# LPC43xx register map
File version: 10
CPU: CM4 r0p0, little endian, no MPU, no FPU, 3 interrupt priority bits
Registers are 32-bit, read-write, reset 0x0 unless marked. A register's access mark holds for its fields unless they carry their own. Offsets are from the block's base; [hi:lo] are bit positions; {n}, {i} and the like mark numbered series; 'fields as' and 'values as' point back to an identical list.

## SCU — System Control Unit (SCU) I/O configuration
Base 0x40086000
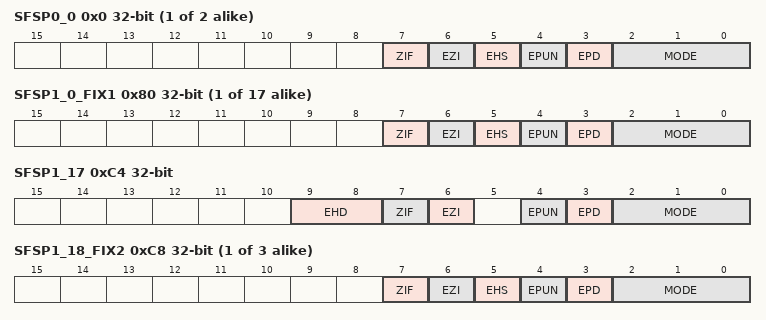
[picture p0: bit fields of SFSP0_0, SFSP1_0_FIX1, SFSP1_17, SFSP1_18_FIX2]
{0x0+4i} SFSP0_{i} (i=0..1) — Pin configuration register for pins P0
  [7] ZIF — Input glitch filter. Disable the input glitch filter for clocking signals higher than 30 MHz.
    0=ENABLE_INPUT_GLITCH (Enable input glitch filter); 1=DISABLE_INPUT_GLITCH (Disable input glitch filter)
  [6] EZI — Input buffer enable. The input buffer is disabled by default at reset and must be enabled for receiving.
    0=DISABLE_INPUT_BUFFER; 1=ENABLE_INPUT_BUFFER
  [5] EHS — Select Slew rate.
    0=SLOW_LOW_NOISE_WITH (Slow (low noise with medium speed)); 1=FAST_MEDIUM_NOISE_W (Fast (medium noise with fast speed))
  [4] EPUN — Disable pull-up resistor at pad. By default, the pull-up resistor is enabled at reset.
    0=ENABLE_PULL_UP (Enable pull-up. Enable both pull-down resistor and pull-up resistor for repeater mode.); 1=DISABLE_PULL_UP
  [3] EPD — Enable pull-down resistor at pad.
    0=DISABLE_PULL_DOWN; 1=ENABLE_PULL_DOWN (Enable pull-down.Enable both pull-down resistor and pull-up resistor for repeater mode.)
  [2:0] MODE — Select pin function.
    0=FUNCTION_0_DEFAULT; {v}=FUNCTION_{v} (v=1..7)
{0x80+4i} SFSP1_{i}_FIX1 (i=0..16) — Pin configuration register for pins P1
  fields as SFSP0_0
0xC4 SFSP1_17 — Pin configuration register for pins P1_17
  [9:8] EHD — Select drive strength.
    0=NORMAL_DRIVE_4_MA_D (Normal-drive: 4 mA drive strength); 1=MEDIUM_DRIVE_8_MA_D (Medium-drive: 8 mA drive strength); 2=HIGH_DRIVE_14_MA_DR (High-drive: 14 mA drive strength); 3=ULTRA_HIGH_DRIVE_20 (Ultra high-drive: 20 mA drive strength)
  [7] ZIF — Input glitch filter. Disable the input glitch filter for clocking signals higher than 30 MHz.
    values as SFSP0_0.ZIF
  [6] EZI — Input buffer enable. The input buffer is disabled by default at reset but must be enabled to transfer data from the I/O buffer to the pad.
    0=DISABLE_INPUT_BUFFER; 1=ENABLE_INPUT_BUFFER
  [4] EPUN — Disable pull-up resistor at pad. By default, the pull-up resistor is enabled at reset.
    values as SFSP0_0.EPUN
  [3] EPD — Enable pull-down resistor at pad.
    0=DISABLE_PULL_DOWN; 1=ENABLE_PULL_DOWN (Enable pull-down. Enable both pull-down resistor and pull-up resistor for repeater mode.)
  [2:0] MODE — Select pin function.
    0=FUNCTION_0_DEFAULT; {v}=FUNCTION_{v} (v=1..7)
{0x80+4i} SFSP1_{i}_FIX2 (i=18..20) — Pin configuration register for pins P1
  fields as SFSP0_0
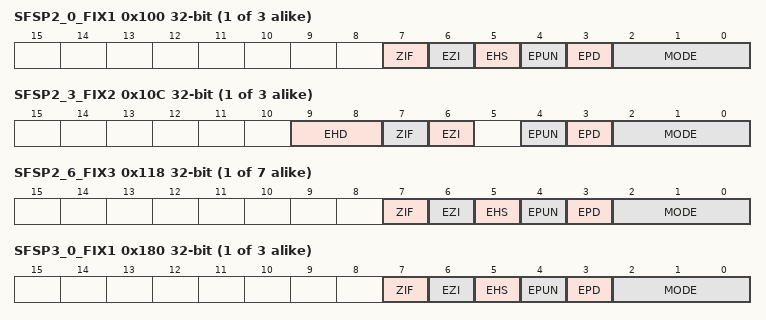
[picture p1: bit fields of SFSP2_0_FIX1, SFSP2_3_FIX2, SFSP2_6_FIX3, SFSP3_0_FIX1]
{0x100+4i} SFSP2_{i}_FIX1 (i=0..2) — Pin configuration register for pins P2
  fields as SFSP0_0
{0x100+4i} SFSP2_{i}_FIX2 (i=3..5) — Pin configuration register for pins P2
  fields as SFSP1_17
{0x100+4i} SFSP2_{i}_FIX3 (i=6..12) — Pin configuration register for pins P2
  fields as SFSP0_0
{0x180+4i} SFSP3_{i}_FIX1 (i=0..2) — Pin configuration register for pins P3
  fields as SFSP0_0
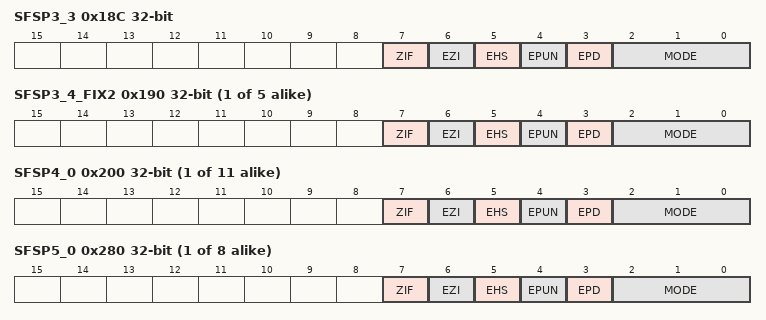
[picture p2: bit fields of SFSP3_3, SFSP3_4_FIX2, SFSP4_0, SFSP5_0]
0x18C SFSP3_3 — Pin configuration register for pins P3
  [7] ZIF — Input glitch filter. Disable the input glitch filter for clocking signals higher than 30 MHz.
    0=ENABLE_INPUT_FILTER; 1=DISABLE_INPUT_FILTER
  [6] EZI — Input buffer enable. The input buffer is disabled by default at reset and must be enabled for receiving.
    0=DISABLE_INPUT_BUFFER; 1=ENABLE_INPUT_BUFFER
  [5] EHS — Slew rate
    0=FAST_LOW_NOISE_WITH (Fast (low noise with fast speed)); 1=HIGH_SPEED_MEDIUM_N (High-speed (medium noise with high speed))
  [4] EPUN — Disable pull-up resistor at pad. By default, the pull-up resistor is enabled at reset.
    values as SFSP0_0.EPUN
  [3] EPD — Enable pull-down resistor at pad.
    values as SFSP1_17.EPD
  [2:0] MODE — Select pin function.
    0=FUNCTION_0_DEFAULT; {v}=FUNCTION_{v} (v=1..7)
{0x180+4i} SFSP3_{i}_FIX2 (i=4..8) — Pin configuration register for pins P3
  fields as SFSP0_0
{0x200+4i} SFSP4_{i} (i=0..10) — Pin configuration register for pins P4
  fields as SFSP0_0
{0x280+4i} SFSP5_{i} (i=0..7) — Pin configuration register for pins P5
  fields as SFSP0_0
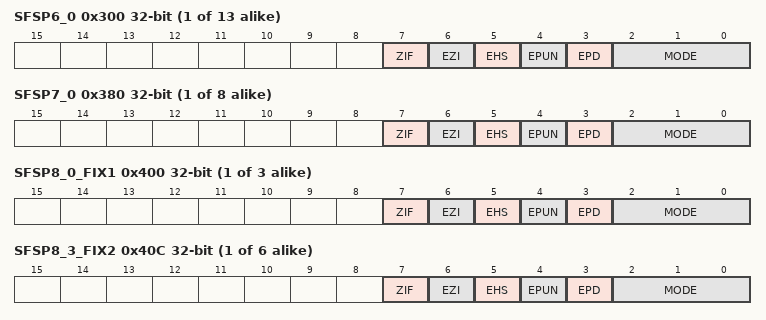
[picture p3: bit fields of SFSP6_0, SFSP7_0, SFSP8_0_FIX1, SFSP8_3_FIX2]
{0x300+4i} SFSP6_{i} (i=0..12) — Pin configuration register for pins P6
  fields as SFSP0_0
{0x380+4i} SFSP7_{i} (i=0..7) — Pin configuration register for pins P7
  fields as SFSP0_0
{0x400+4i} SFSP8_{i}_FIX1 (i=0..2) — Pin configuration register for pins P8
  fields as SFSP0_0
{0x400+4i} SFSP8_{i}_FIX2 (i=3..8) — Pin configuration register for pins P8
  fields as SFSP0_0
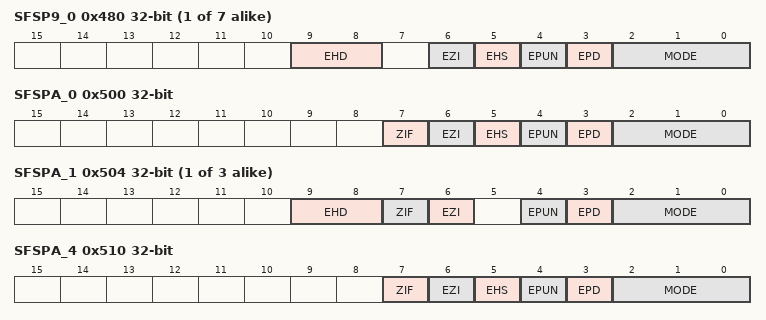
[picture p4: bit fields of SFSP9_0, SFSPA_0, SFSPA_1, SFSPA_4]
{0x480+4i} SFSP9_{i} (i=0..6) — Pin configuration register for pins P9
  [9:8] EHD — Select drive strength
    0=STANDARD_DRIVE_4_MA (Standard drive: 4 mA drive strength); 1=MEDIUM_DRIVE_8_MA_D (Medium drive: 8 mA drive strength); 2=HIGH_DRIVE_14_MA_DR (High drive: 14 mA drive strength); 3=ULTRA_HIGH_DRIVE_20 (Ultra-high drive: 20 mA drive strength)
  [6] EZI — Input buffer enable. The input buffer is disabled by default at reset but must be enabled to transfer data from the I/O buffer to the pad.
    0=DISABLE_INPUT_BUFFER; 1=ENABLE_INPUT_BUFFER
  [5] EHS — Slew rate
    0=SLOW; 1=FAST
  [4] EPUN — Disable pull-up resistor at pad. By default, the pull-up resistor is enabled at reset.
    0=ENABLE_PULL_UP; 1=DISABLE_PULL_UP
  [3] EPD — Enable pull-down resistor at pad
    0=DISABLE_PULL_DOWN_; 1=ENABLE_PULL_DOWN_
  [2:0] MODE — Select pin function
    0=FUNCTION_0_DEFAULT; {v}=FUNCTION_{v} (v=1..7)
0x500 SFSPA_0 — Pin configuration register for pins PA
  fields as SFSP0_0
{0x500+4i} SFSPA_{i} (i=1..3) — Pin configuration register for pins PA
  fields as SFSP1_17
0x510 SFSPA_4 — Pin configuration register for pins PA
  fields as SFSP0_0
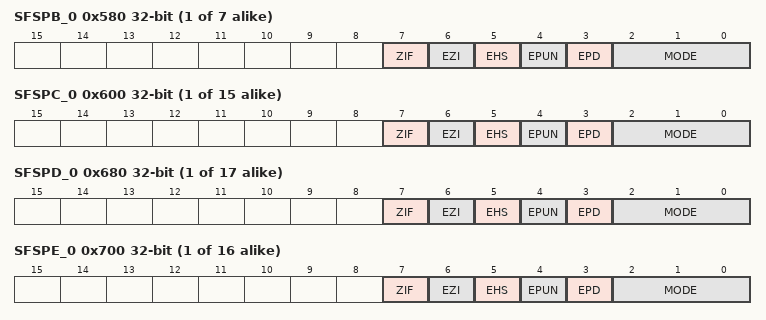
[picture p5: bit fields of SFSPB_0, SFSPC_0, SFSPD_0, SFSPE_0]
{0x580+4i} SFSPB_{i} (i=0..6) — Pin configuration register for pins PB
  fields as SFSP0_0
{0x600+4i} SFSPC_{i} (i=0..14) — Pin configuration register for pins PC
  fields as SFSP0_0
{0x680+4i} SFSPD_{i} (i=0..16) — Pin configuration register for pins PD
  fields as SFSP0_0
{0x700+4i} SFSPE_{i} (i=0..15) — Pin configuration register for pins PE
  fields as SFSP0_0
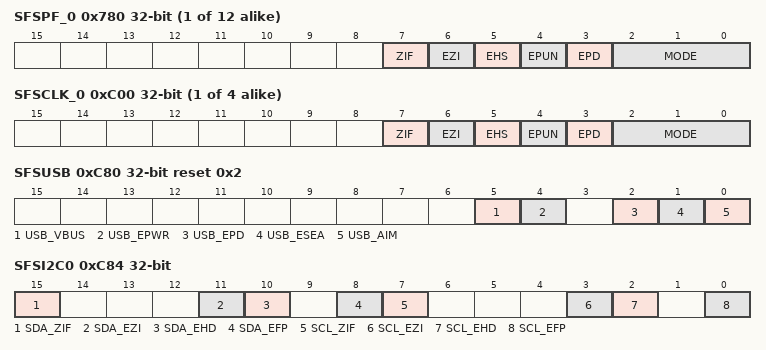
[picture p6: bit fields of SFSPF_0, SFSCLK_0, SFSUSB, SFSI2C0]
{0x780+4i} SFSPF_{i} (i=0..11) — Pin configuration register for pins PF
  fields as SFSP0_0
{0xC00+4i} SFSCLK_{i} (i=0..3) — Pin configuration register for pins CLK
  fields as SFSP3_3
0xC80 SFSUSB reset 0x2 — Pin configuration register for pins USB1_DM and USB1_DP
  [5] USB_VBUS — Enable the vbus_valid signal. This signal is monitored by the USB1 block. Use this bit for software de-bouncing of the VBUS sense signal or to indicate the VBUS state to the USB1 controller when the VBUS signal is present but the USB1_VBUS function is not connected in the SFSP2_5 register. The setting of this bit has no effect if the USB1_VBUS function of pin P2_5 is enabled through the SFSP2_5 register.
    0=VBUS_SIGNAL_LOW_OR_I (VBUS signal LOW or inactive); 1=VBUS_SIGNAL_HIGH_OR (VBUS signal HIGH or active)
  [4] USB_EPWR — Power mode.
    0=POWER_SAVING_MODE_S (Power saving mode (Suspend mode)); 1=NORMAL_MODE
  [2] USB_EPD — Enable pull-down connect.
    0=PULL_DOWN_DISCONNECT (Pull-down disconnected); 1=PULL_DOWN_CONNECTED
  [1] USB_ESEA — Control signal for differential input or single input.
    1=SINGLE_INPUT (Single input. Enables USB1. Use with the on-chip full-speed PHY.)
  [0] USB_AIM — Differential data input AIP/AIM.
    0=GOING_LOW_WITH_FULL (Going LOW with full speed edge rate); 1=GOING_HIGH_WITH_FULL (Going HIGH with full speed edge rate)
0xC84 SFSI2C0 — Pin configuration register for I2C0-bus pins
  [15] SDA_ZIF — Enable or disable input glitch filter for the SDA pin. The filter time constant is determined by bit SDA_EFP.
    0=ENABLE_INPUT_FILTER; 1=DISABLE_INPUT_FILTER
  [11] SDA_EZI — Enable the input receiver for the SDA pin. Always write a 1 to this bit when using the I2C0.
    0=DISABLED; 1=ENABLED
  [10] SDA_EHD — Select I2C mode for the SDA pin.
    0=STANDARDFAST_MODE (Standard/Fast mode transmit); 1=FAST_MODE_PLUS_TRANS (Fast-mode Plus transmit)
  [8] SDA_EFP — Select input glitch filter time constant for the SDA pin.
    0=50_NS_GLITCH_FILTER; 1=3_NS_GLITCH_FILTER
  [7] SCL_ZIF — Enable or disable input glitch filter for the SCL pin. The filter time constant is determined by bit EFP.
    0=ENABLE_INPUT_FILTER; 1=DISABLE_INPUT_FILTER
  [3] SCL_EZI — Enable the input receiver for the SCL pin. Always write a 1 to this bit when using the I2C0.
    0=DISABLED; 1=ENABLED
  [2] SCL_EHD — Select I2C mode for the SCL pin.
    values as SDA_EHD
  [0] SCL_EFP — Select input glitch filter time constant for the SCL pin.
    0=50_NS_GLITCH_FILTER; 1=3_NS_GLITCH_FILTER
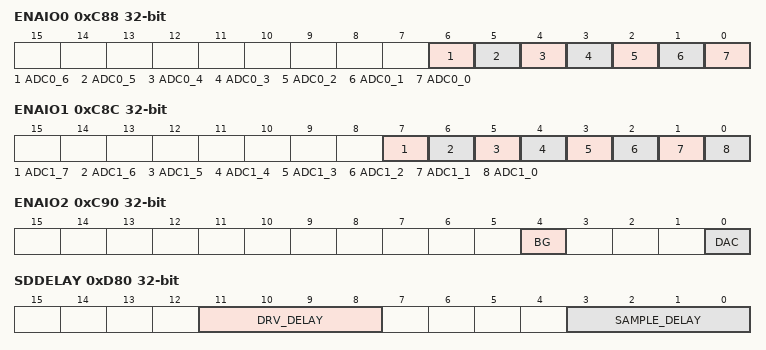
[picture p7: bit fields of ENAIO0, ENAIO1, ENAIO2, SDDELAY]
0xC88 ENAIO0 — ADC0 function select register
  [6] ADC0_6 — Select ADC0_6
    0=DIGITAL_FUNCTION_SEL (Digital function selected on pin PB_6.); 1=ANALOG_FUNCTION_ADC0 (Analog function ADC0_6 selected on pin PB_6.)
  [5] ADC0_5 — Select ADC0_5
    0=DIGITAL_FUNCTION_SEL (Digital function selected on pin PF_10.); 1=ANALOG_FUNCTION_ADC0 (Analog function ADC0_5 selected on pin PF_10.)
  [4] ADC0_4 — Select ADC0_4
    0=DIGITAL_FUNCTION_SEL (Digital function selected on pin P7_4.); 1=ANALOG_FUNCTION_ADC0 (Analog function ADC0_4 selected on pin P7_4.)
  [3] ADC0_3 — Select ADC0_3
    0=DIGITAL_FUNCTION_SEL (Digital function selected on pin P7_5.); 1=ANALOG_FUNCTION_ADC0 (Analog function ADC0_3 selected on pin P7_5.)
  [2] ADC0_2 — Select ADC0_2
    0=DIGITAL_FUNCTION_SEL (Digital function selected on pin PF_8.); 1=ANALOG_FUNCTION_ADC0 (Analog function ADC0_2 selected on pin PF_8.)
  [1] ADC0_1 — Select ADC0_1
    0=DIGITAL_FUNCTION_SEL (Digital function selected on pin P4_1.); 1=ANALOG_FUNCTION_ADC0 (Analog function ADC0_1 selected on pin P4_1.)
  [0] ADC0_0 — Select ADC0_0
    0=DIGITAL_FUNCTION_SEL (Digital function selected on pin P4_3.); 1=ANALOG_FUNCTION_ADC0 (Analog function ADC0_0 selected on pin P4_3)
0xC8C ENAIO1 — ADC1 function select register
  [7] ADC1_7 — Select ADC1_7.
    0=DIGITAL_FUNCTION_SEL (Digital function selected on pin PF_7.); 1=ANALOG_FUNCTION_ADC1 (Analog function ADC1_7 selected on pin PF_7.)
  [6] ADC1_6 — Select ADC1_6
    0=DIGITAL_FUNCTION_SEL (Digital function selected on pin P7_7.); 1=ANALOG_FUNCTION_ADC1 (Analog function ADC1_6 selected on pin P7_7.)
  [5] ADC1_5 — Select ADC1_5
    0=DIGITAL_FUNCTION_SEL (Digital function selected on pin PF_11.); 1=ANALOG_FUNCTION_ADC1 (Analog function ADC1_5 selected on pin PF_11.)
  [4] ADC1_4 — Select ADC1_4
    0=DIGITAL_FUNCTION_SEL (Digital function selected on pin PF_5.); 1=ANALOG_FUNCTION_ADC1 (Analog function ADC1_4 selected on pin PF_5.)
  [3] ADC1_3 — Select ADC1_3
    0=DIGITAL_FUNCTION_SEL (Digital function selected on pin PF_6.); 1=ANALOG_FUNCTION_ADC1 (Analog function ADC1_3 selected on pin PF_6.)
  [2] ADC1_2 — Select ADC1_2
    0=DIGITAL_FUNCTION_SEL (Digital function selected on pin PF_9.); 1=ANALOG_FUNCTION_ADC1 (Analog function ADC1_2 selected on pin PF_9.)
  [1] ADC1_1 — Select ADC1_1
    0=DIGITAL_FUNCTION_SEL (Digital function selected on pin PC_0.); 1=ANALOG_FUNCTION_ADC1 (Analog function ADC1_1 selected on pin PC_0.)
  [0] ADC1_0 — Select ADC1_0
    0=DIGITAL_FUNCTION_SEL (Digital function selected on pin PC_3.); 1=ANALOG_FUNCTION_ADC1 (Analog function ADC1_0 selected on pin PC_3.)
0xC90 ENAIO2 — Analog function select register
  [4] BG — Select band gap output. To measure the band gap, disable the pull-up on pin PF_7 and connect PF_7 to the digital pad. Do not use the digital pad nor the ADC1_7 on the board when measuring the band gap (see Section 15.4.8.1).
    0=DIGITAL_FUNCTION_SEL (Digital function selected on pin PF_7.); 1=BAND_GAP_OUTPUT_SELE (Band gap output selected for pin PF_7.)
  [0] DAC — Select DAC
    0=DIGITAL_FUNCTION_SEL (Digital function selected on pin P4_4.); 1=ANALOG_FUNCTION_DAC (Analog function DAC selected on pin P4_4.)
0xD00 EMCDELAYCLK — EMC clock delay register
  [15:0] CLK_DELAY — EMC_CLKn SDRAM clock output delay. 0x0 = no delay 0x1111 approximately 0.5 ns delay 0x2222 approximately 1.0 ns delay 0x3333 approximately 1.5 ns delay 0x4444 approximately 2.0 ns delay 0x5555 approximately 2.5 ns delay 0x6666 approximately 3.0 ns delay 0x7777 approximately 3.5 ns delay
0xD80 SDDELAY — SD/MMC sample and drive delay register
  [11:8] DRV_DELAY — SD/MMC drive delay. The delay value is DRV_DELAY x 0.5 ns. The values DRV_DELAY = 0 and DRV_DELAY = 1 are not allowed.
  [3:0] SAMPLE_DELAY — SD/MMC sample delay. The delay value is SAMPLE_DELAY x 0.5 ns.
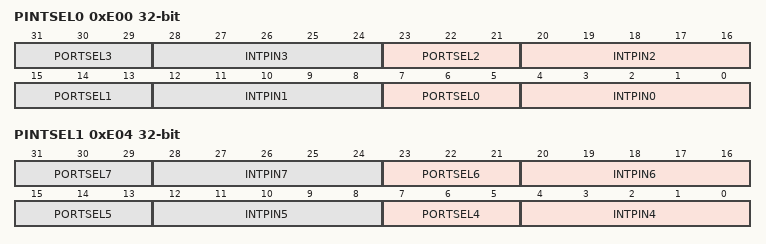
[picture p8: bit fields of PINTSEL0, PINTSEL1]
0xE00 PINTSEL0 — Pin interrupt select register for pin interrupts 0 to 3.
  [8n+7:8n+5] PORTSEL{n} (n=0..3) — Pin interrupt {n}: Select the port for the pin number to be selected in the INTPIN{n} bits of this register.
    {v}=GPIO_PORT_{v} (v=0..7)
  [8n+4:8n] INTPIN{n} (n=0..3) — Pint interrupt {n}: Select the pin number within the GPIO port selected by the PORTSEL{n} bit in this register.
0xE04 PINTSEL1 — Pin interrupt select register for pin interrupts 4 to 7.
  [8n-25:8n-27] PORTSEL{n} (n=4..7) — Pin interrupt {n}: Select the port for the pin number to be selected in the INTPIN{n} bits of this register.
    {v}=GPIO_PORT_{v} (v=0..7)
  [8n-28:8n-32] INTPIN{n} (n=4..7) — Pint interrupt {n}: Select the pin number within the GPIO port selected by the PORTSEL{n} bit in this register.
